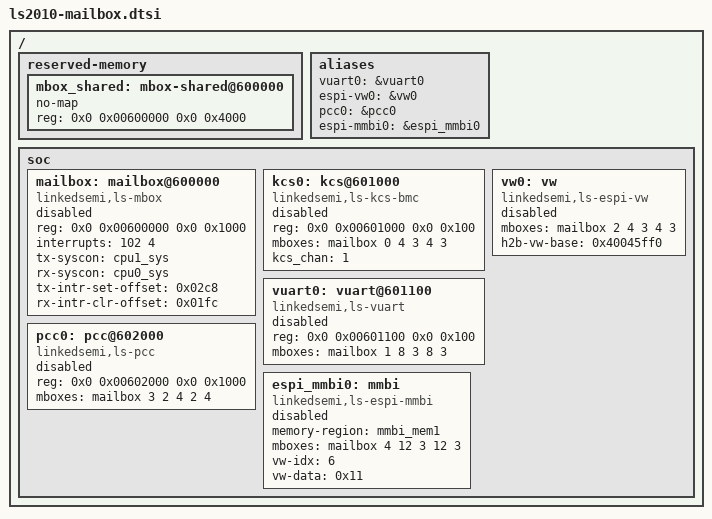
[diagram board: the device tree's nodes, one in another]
// SPDX-License-Identifier: (GPL-2.0 OR MIT)
/* Copyright (c) 2026 Linkedsemi */
/* LS2010 mailbox (E906 <-> C908 inter-core) nodes — split out of
 * ls2010-common.dtsi so the mailbox eSPI client subsystem lives in one
 * self-contained file.  Channels covered:
 *   ch0 — KCS      (IPMI KCS over mailbox)
 *   ch1 — VUART    (host SOL console heartbeat)
 *   ch2 — VWire    (multi-group Down-VWire over mailbox)
 *   ch3 — Port80   (POST code capture)
 *   ch4 — MMBI     (Mailbox-Managed BMC Interface, platform client)
 *
 * The shared window and its layout are owned by the E906 firmware
 * (Zephyr mbox driver, initiator role); see the mailbox node below.
 * Included by ls2010-common.dtsi; the /reserved-memory, /aliases and /soc
 * blocks merge with the ones in ls2010-common.dtsi, so shared-memory
 * reservations, aliases and mailbox client nodes stay in their original
 * parents and remain visible to phandle consumers in the same compilation
 * unit.  All client nodes default to status = "disabled"; board DTS files
 * enable the ones they need.
 */

/ {
	reserved-memory {
		/* E906 <-> C908 mailbox shared SRAM (16K), non-cacheable */
		mbox_shared: mbox-shared@600000 {
			no-map;
			reg = <0x0 0x00600000 0x0 0x4000>;
		};

	};

	aliases {
		vuart0 = &vuart0;
		espi-vw0 = &vw0;
		pcc0 = &pcc0;
		espi-mmbi0 = &espi_mmbi0;
	};

	soc {
		mailbox: mailbox@600000 {
			compatible = "linkedsemi,ls-mbox";
			reg = <0x0 0x00600000 0x0 0x1000>;	/* shared SRAM (RX/TX FIFOs) */
			interrupts = <102 4>;
			#mbox-cells = <5>;	/* chan, tx_w, tx_d, rx_w, rx_d */
			tx-syscon = <&cpu1_sys>;	/* CPU1_SYS_CFG: TX doorbell */
			rx-syscon = <&cpu0_sys>;	/* CPU0_SYS_CFG: RX intr clear */
			tx-intr-set-offset = <0x02c8>;
			rx-intr-clr-offset = <0x01fc>;
			status = "disabled";
		};

		kcs0: kcs@601000 {
			compatible = "linkedsemi,ls-kcs-bmc";
			reg = <0x0 0x00601000 0x0 0x100>;	/* reg#0 shadow host_kcs_env */
			mboxes = <&mailbox 0 4 3 4 3>;	/* chan0, tx 4B×3, rx 4B×3 */
			kcs_chan = <1>;
			status = "disabled";
		};

		vuart0: vuart@601100 {
			compatible = "linkedsemi,ls-vuart";
			reg = <0x0 0x00601100 0x0 0x100>;	/* reg#0 host_vuart_fifo (PLACEHOLDER; independent of mbox data FIFOs, see above) */
			mboxes = <&mailbox 1 8 3 8 3>;	/* chan1, tx 8B×3, rx 8B×3 */
			status = "disabled";
		};

		/*
		 * ch3: VWire (multi-group Down-VWire) over mailbox.
		 *
		 * The E906 (zephyr/drivers/espi/espi_ls.c) sends a
		 * struct espi_vwire_msg { u8 vw_idx; u8 vw_val; } event for
		 * every changed down-VWire group: 2 (SLP_S3/S4/S5), 3
		 * (SUS_STAT#, PLTRST#, OOB_RST_WARN), 7 (HOST_RST_WARN,
		 * SMIOUT#, NMIOUT#) and the peripheral groups listed in the
		 * E906's ms-vw-idx property.  The message only announces the
		 * event; the levels are read by Linux from the shared
		 * struct espi_h2b_vw_base:
		 *
		 *	struct espi_h2b_vw_base {
		 *		u8 s02_ms;
		 *		u8 s03_ms;
		 *		u8 s07_ms;
		 *		u8 ms_vw_val[8];
		 *	};
		 *
		 * h2b-vw-base is the C908-view address of that structure —
		 * the sysevent mirror at the tail of the E906's eSPI0
		 * controller window (0x40045000 + 0xff0), the same value the
		 * E906 espi_bmc_ls driver consumes.  Linux maps it for the
		 * RX path; upstream VW updates travel in the mailbox message
		 * itself (LS_ESPI_VW_PUT_VW ioctl).
		 *
		 *   - mboxes chan2 = Linux-side channel for VW events; the
		 *     width/depth cells must match the E906 firmware's mbox
		 *     node exactly.
		 *   - status = "disabled": board DTS overrides to "okay".
		 */
		vw0: vw {
			compatible = "linkedsemi,ls-espi-vw";
			mboxes = <&mailbox 2 4 3 4 3>;	/* chan2, tx 4B×3, rx 4B×3 */
			h2b-vw-base = <0x40045ff0>;	/* C908 view of struct espi_h2b_vw_base */
			status = "disabled";
		};

		/*
		 * ch3: Port80 (POST code capture) over mailbox.
		 *
		 * The E906 firmware
		 * (soc/linkedsemi/common/espi_lpc/espi_lpc_host_pcc.c) snoops
		 * host I/O writes to the ports listed in its host_pcc node
		 * (80h-83h) and pushes each captured code into the shared
		 * struct host_pcc_env { struct fifo_env fifo; struct
		 * pcc_data data[128]; }, then raises a mailbox interrupt to
		 * announce it.  The mailbox message carries no payload that
		 * Linux uses; the linkedsemi-pcc driver drains the shared
		 * FIFO on the event and exposes the codes as 2-byte records
		 * through /dev/linkedsemi-pccN with read(2)/poll(2).  Linux
		 * never sends on this channel; it is receive-only.
		 *
		 *   - reg = C908 view of the firmware's host_pcc_env in the
		 *     shared SRAM (the E906's pcc-env-addr property).
		 *   - mboxes chan3 = Linux-side channel for the post code
		 *     events; the width/depth cells must match the E906
		 *     firmware's mbox node exactly (2-byte records).
		 *   - status = "disabled": board DTS overrides to "okay".
		 */
		pcc0: pcc@602000 {
			compatible = "linkedsemi,ls-pcc";
			reg = <0x0 0x00602000 0x0 0x1000>;	/* struct host_pcc_env, 12B env + 128×2B */
			mboxes = <&mailbox 3 2 4 2 4>;	/* chan3, tx 2B×4, rx 2B×4 */
			status = "disabled";
		};

		/*
		 * ch4: MMBI (Memory Mapped Bus Interface) over mailbox.
		 *
		 * The MMBI region is the no-map reserved-memory region
		 * mmbi_mem1, mapped by the linkedsemi-espi-mmbi driver.
		 * After initializing the MMBI descriptor the driver
		 * announces the region's physical base and size to the E906
		 * firmware with an MMBI_INFO message; the firmware
		 * (soc/linkedsemi/common/espi_lpc/espi_lpc_host_mmbi.c)
		 * then serves host MMBI accesses from it.  BMC-to-host
		 * interrupts are reported with MMBI_HOST_INT on the virtual
		 * wires configured by vw-idx/vw-data (6/0x11 = SCI, 0/1 =
		 * edge groups); MMBI_HOST_RWS_WR sent by the firmware
		 * announces host pointer updates.
		 *
		 *   - mboxes chan4 = Linux-side MMBI channel; the width/depth
		 *     cells must match the E906 firmware's mbox node exactly
		 *     (12-byte records, one struct ls_mmbi_msg).
		 *   - vw-idx/vw-data are the virtual wire index/data carried
		 *     in MMBI_HOST_INT.
		 *   - status = "disabled": board DTS overrides to "okay".
		 */
		espi_mmbi0: mmbi {
			compatible = "linkedsemi,ls-espi-mmbi";
			memory-region = <&mmbi_mem1>;
			mboxes = <&mailbox 4 12 3 12 3>;	/* chan4, tx 12B×3, rx 12B×3 */
			vw-idx = <6>;				/* VW index in MMBI_HOST_INT */
			vw-data = <0x11>;			/* VW data in MMBI_HOST_INT (SCI) */
			status = "disabled";
		};

	};
};
